VERSION ""

NS_ :

BS_:

BU_: measure sec_3 sec_1 pri_3 pri_1_xy

BO_ 1795 Tx_msg2_100ms: 1 measure
 SG_ any_Signal_3 : 0|8@1- (1,0) [0|0] "" Vector__XXX

BO_ 1794 Tx_msg1_100ms: 1 measure
 SG_ any_Signal_2 : 0|8@1- (1,0) [0|0] "" Vector__XXX

BO_ 1793 Tx_msg_20ms: 1 measure
 SG_ any_Signal_1 : 0|8@1- (1,0) [0|0] "" Vector__XXX

BO_ 345 Empty_Message_8: 0 sec_3

BO_ 357 Empty_Message_7: 8 measure

BO_ 0 test_real: 8 Vector__XXX
 SG_ real_Signal : 0|32@1- (1,0) [0|0] ""  measure

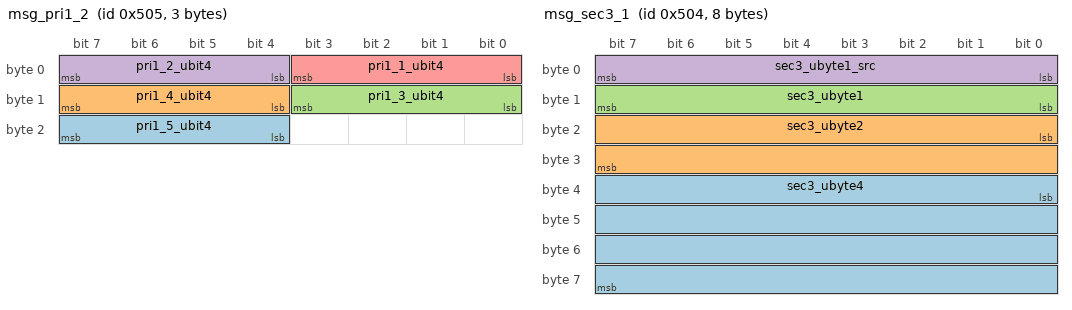
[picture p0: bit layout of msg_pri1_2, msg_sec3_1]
BO_ 1285 msg_pri1_2: 3 pri_1_xy
 SG_ pri1_5_ubit4 : 20|4@1+ (1,0) [0|15] ""  measure
 SG_ pri1_4_ubit4 : 12|4@1+ (1,0) [0|15] ""  measure
 SG_ pri1_3_ubit4 : 8|4@1+ (1,0) [0|15] ""  measure
 SG_ pri1_2_ubit4 : 4|4@1+ (1,0) [0|15] ""  measure
 SG_ pri1_1_ubit4 : 0|4@1+ (1,0) [0|15] ""  measure

BO_ 1284 msg_sec3_1: 8 sec_3
 SG_ sec3_ubyte4 : 32|32@1+ (7,0) [0|30064771065] ""  measure
 SG_ sec3_ubyte2 : 16|16@1+ (5,0) [0|327675] ""  measure
 SG_ sec3_ubyte1 : 8|8@1+ (3,-10) [-10|755] ""  measure
 SG_ sec3_ubyte1_src : 0|8@1+ (2,10) [10|520] ""  measure

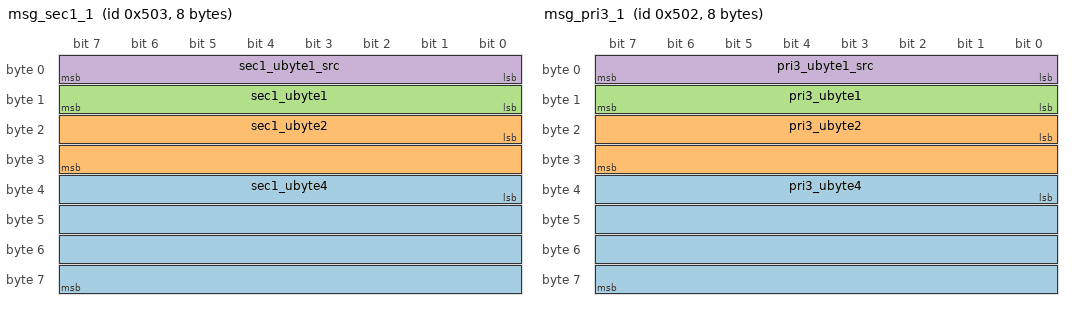
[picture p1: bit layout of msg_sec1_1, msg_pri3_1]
BO_ 1283 msg_sec1_1: 8 sec_1
 SG_ sec1_ubyte4 : 32|32@1+ (11,15) [15|47244640260] ""  measure
 SG_ sec1_ubyte2 : 16|16@1+ (7,0) [0|458745] ""  measure
 SG_ sec1_ubyte1 : 8|8@1+ (5,-10) [-10|1265] ""  measure
 SG_ sec1_ubyte1_src : 0|8@1+ (2,10) [10|520] ""  measure

BO_ 1282 msg_pri3_1: 8 pri_3
 SG_ pri3_ubyte4 : 32|32@1+ (7,0) [0|30064771065] ""  measure
 SG_ pri3_ubyte2 : 16|16@1+ (5,0) [0|327675] ""  measure
 SG_ pri3_ubyte1 : 8|8@1+ (3,-10) [-10|755] ""  measure
 SG_ pri3_ubyte1_src : 0|8@1+ (2,10) [10|520] ""  measure

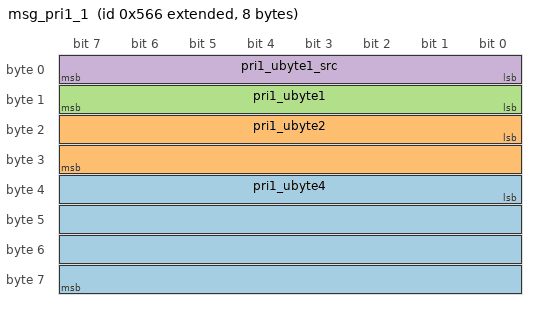
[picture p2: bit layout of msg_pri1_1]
BO_ 2147485030 msg_pri1_1: 8 pri_1_xy
 SG_ pri1_ubyte4 : 32|32@1+ (11,15) [15|47244640260] ""  measure
 SG_ pri1_ubyte2 : 16|16@1+ (7,0) [0|458745] ""  measure
 SG_ pri1_ubyte1 : 8|8@1+ (5,-10) [-10|1265] ""  measure
 SG_ pri1_ubyte1_src : 0|8@1+ (2,10) [10|520] ""  measure

BA_DEF_  "BusType" STRING ;
BA_DEF_ BO_  "GenMsgCycleTime" INT 0 3600000;
BA_DEF_DEF_  "BusType" "";
BA_DEF_DEF_  "GenMsgCycleTime" 0;
BA_ "BusType" "CAN";
BA_ "GenMsgCycleTime" BO_ 1795 100;
BA_ "GenMsgCycleTime" BO_ 1794 100;
BA_ "GenMsgCycleTime" BO_ 1793 20;
BA_ "GenMsgCycleTime" BO_ 2147485030 100;
SIG_VALTYPE_ 0 real_Signal : 1;
